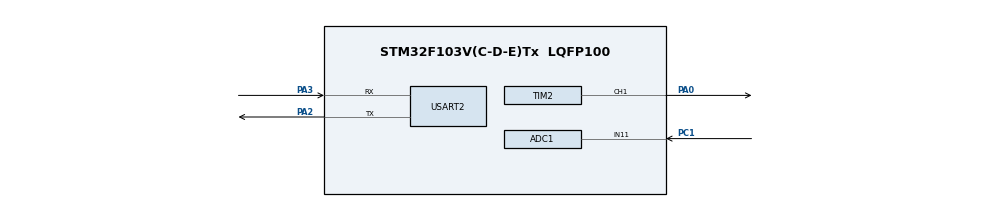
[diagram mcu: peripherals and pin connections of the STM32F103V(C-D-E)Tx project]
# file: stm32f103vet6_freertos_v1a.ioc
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ADC1.Channel-0\#ChannelRegularConversion=ADC_CHANNEL_11
ADC1.ContinuousConvMode=ENABLE
ADC1.NbrOfConversionFlag=1
ADC1.Rank-0\#ChannelRegularConversion=1
ADC1.SamplingTime-0\#ChannelRegularConversion=ADC_SAMPLETIME_1CYCLE_5
ADC1.master=1
FREERTOS.Tasks01=ControlTask,2,128,StartControlTask,Default,NULL,Dynamic,NULL,NULL;MonitorTask,0,128,StartMonitorTask,Default,NULL,Dynamic,NULL,NULL
FREERTOS.configUSE_NEWLIB_REENTRANT=1
Mcu.Family=STM32F1
Mcu.Name=STM32F103V(C-D-E)Tx
Mcu.Package=LQFP100
NVIC.PriorityGroup=NVIC_PRIORITYGROUP_4
NVIC.TIM3_IRQn=true\:15\:0\:false\:false\:true\:false\:false\:true\:true
NVIC.TimeBase=TIM3_IRQn
NVIC.TimeBaseIP=TIM3
OSC_IN.Mode=HSE-External-Oscillator
OSC_IN.Signal=RCC_OSC_IN
OSC_OUT.Mode=HSE-External-Oscillator
OSC_OUT.Signal=RCC_OSC_OUT
PA0-WKUP.Signal=S_TIM2_CH1_ETR
PA13.Mode=Serial_Wire
PA13.Signal=SYS_JTMS-SWDIO
PA14.Mode=Serial_Wire
PA14.Signal=SYS_JTCK-SWCLK
PA2.Mode=Asynchronous
PA2.Signal=USART2_TX
PA3.Mode=Asynchronous
PA3.Signal=USART2_RX
PC1.Signal=ADCx_IN11
ProjectManager.HeapSize=0x200
ProjectManager.StackSize=0x400
ProjectManager.TargetToolchain=STM32CubeIDE
RCC.APB1Freq_Value=8000000
RCC.APB2Freq_Value=8000000
SH.ADCx_IN11.0=ADC1_IN11,IN11
SH.S_TIM2_CH1_ETR.0=TIM2_CH1,PWM Generation1 CH1
TIM2.AutoReloadPreload=TIM_AUTORELOAD_PRELOAD_ENABLE
TIM2.Channel-PWM\ Generation1\ CH1=TIM_CHANNEL_1
TIM2.Period=99
TIM2.Prescaler=79
USART2.VirtualMode=VM_ASYNC
VP_FREERTOS_VS_CMSIS_V1.Mode=CMSIS_V1
VP_SYS_VS_tim3.Mode=TIM3
VP_TIM2_VS_ClockSourceINT.Mode=Internal
board=custom

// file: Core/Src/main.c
/* USER CODE BEGIN Header */
/**
  ******************************************************************************
  * @file           : main.c
  * @brief          : Main program body
  ******************************************************************************
  * @attention
  *
  * Copyright (c) 2026 STMicroelectronics.
  * All rights reserved.
  *
  * This software is licensed under terms that can be found in the LICENSE file
  * in the root directory of this software component.
  * If no LICENSE file comes with this software, it is provided AS-IS.
  *
  ******************************************************************************
  */
/* USER CODE END Header */
#include "main.h"
#include "cmsis_os.h"

ADC_HandleTypeDef hadc1;

TIM_HandleTypeDef htim2;

UART_HandleTypeDef huart2;

osThreadId ControlTaskHandle;
osThreadId MonitorTaskHandle;
/* USER CODE BEGIN PV */
volatile uint32_t adc_val = 0;
volatile uint32_t pwm_val = 0;
/* USER CODE END PV */

void SystemClock_Config(void);
static void MX_GPIO_Init(void);
static void MX_ADC1_Init(void);
static void MX_TIM2_Init(void);
static void MX_USART2_UART_Init(void);
void StartControlTask(void const * argument);
void StartMonitorTask(void const * argument);

int main(void)
{

  /* MCU Configuration--------------------------------------------------------*/

  /* Reset of all peripherals, Initializes the Flash interface and the Systick. */
  HAL_Init();

  /* Configure the system clock */
  SystemClock_Config();

  /* Initialize all configured peripherals */
  MX_GPIO_Init();
  MX_ADC1_Init();
  MX_TIM2_Init();
  MX_USART2_UART_Init();
  /* USER CODE BEGIN 2 */
  HAL_TIM_PWM_Start(&htim2, TIM_CHANNEL_1);
  HAL_ADC_Start(&hadc1);
  /* USER CODE END 2 */

  /* Create the thread(s) */
  /* definition and creation of ControlTask */
  osThreadDef(ControlTask, StartControlTask, osPriorityHigh, 0, 128);
  ControlTaskHandle = osThreadCreate(osThread(ControlTask), NULL);

  /* definition and creation of MonitorTask */
  osThreadDef(MonitorTask, StartMonitorTask, osPriorityNormal, 0, 128);
  MonitorTaskHandle = osThreadCreate(osThread(MonitorTask), NULL);

  /* Start scheduler */
  osKernelStart();

  /* We should never get here as control is now taken by the scheduler */

  /* Infinite loop */
  while (1)
  {

  }
}

void SystemClock_Config(void)
{
  RCC_OscInitTypeDef RCC_OscInitStruct = {0};
  RCC_ClkInitTypeDef RCC_ClkInitStruct = {0};
  RCC_PeriphCLKInitTypeDef PeriphClkInit = {0};

  /** Initializes the RCC Oscillators according to the specified parameters
  * in the RCC_OscInitTypeDef structure.
  */
  RCC_OscInitStruct.OscillatorType = RCC_OSCILLATORTYPE_HSI;
  RCC_OscInitStruct.HSIState = RCC_HSI_ON;
  RCC_OscInitStruct.HSICalibrationValue = RCC_HSICALIBRATION_DEFAULT;
  RCC_OscInitStruct.PLL.PLLState = RCC_PLL_NONE;
  if (HAL_RCC_OscConfig(&RCC_OscInitStruct) != HAL_OK)
  {
    Error_Handler();
  }

  /** Initializes the CPU, AHB and APB buses clocks
  */
  RCC_ClkInitStruct.ClockType = RCC_CLOCKTYPE_HCLK|RCC_CLOCKTYPE_SYSCLK
                              |RCC_CLOCKTYPE_PCLK1|RCC_CLOCKTYPE_PCLK2;
  RCC_ClkInitStruct.SYSCLKSource = RCC_SYSCLKSOURCE_HSI;
  RCC_ClkInitStruct.AHBCLKDivider = RCC_SYSCLK_DIV1;
  RCC_ClkInitStruct.APB1CLKDivider = RCC_HCLK_DIV1;
  RCC_ClkInitStruct.APB2CLKDivider = RCC_HCLK_DIV1;

  if (HAL_RCC_ClockConfig(&RCC_ClkInitStruct, FLASH_LATENCY_0) != HAL_OK)
  {
    Error_Handler();
  }
  PeriphClkInit.PeriphClockSelection = RCC_PERIPHCLK_ADC;
  PeriphClkInit.AdcClockSelection = RCC_ADCPCLK2_DIV2;
  if (HAL_RCCEx_PeriphCLKConfig(&PeriphClkInit) != HAL_OK)
  {
    Error_Handler();
  }
}

static void MX_ADC1_Init(void)
{

  ADC_ChannelConfTypeDef sConfig = {0};

  /** Common config
  */
  hadc1.Instance = ADC1;
  hadc1.Init.ScanConvMode = ADC_SCAN_DISABLE;
  hadc1.Init.ContinuousConvMode = ENABLE;
  hadc1.Init.DiscontinuousConvMode = DISABLE;
  hadc1.Init.ExternalTrigConv = ADC_SOFTWARE_START;
  hadc1.Init.DataAlign = ADC_DATAALIGN_RIGHT;
  hadc1.Init.NbrOfConversion = 1;
  if (HAL_ADC_Init(&hadc1) != HAL_OK)
  {
    Error_Handler();
  }

  /** Configure Regular Channel
  */
  sConfig.Channel = ADC_CHANNEL_11;
  sConfig.Rank = ADC_REGULAR_RANK_1;
  sConfig.SamplingTime = ADC_SAMPLETIME_1CYCLE_5;
  if (HAL_ADC_ConfigChannel(&hadc1, &sConfig) != HAL_OK)
  {
    Error_Handler();
  }

}

static void MX_TIM2_Init(void)
{

  TIM_ClockConfigTypeDef sClockSourceConfig = {0};
  TIM_MasterConfigTypeDef sMasterConfig = {0};
  TIM_OC_InitTypeDef sConfigOC = {0};

  htim2.Instance = TIM2;
  htim2.Init.Prescaler = 79;
  htim2.Init.CounterMode = TIM_COUNTERMODE_UP;
  htim2.Init.Period = 99;
  htim2.Init.ClockDivision = TIM_CLOCKDIVISION_DIV1;
  htim2.Init.AutoReloadPreload = TIM_AUTORELOAD_PRELOAD_ENABLE;
  if (HAL_TIM_Base_Init(&htim2) != HAL_OK)
  {
    Error_Handler();
  }
  sClockSourceConfig.ClockSource = TIM_CLOCKSOURCE_INTERNAL;
  if (HAL_TIM_ConfigClockSource(&htim2, &sClockSourceConfig) != HAL_OK)
  {
    Error_Handler();
  }
  if (HAL_TIM_PWM_Init(&htim2) != HAL_OK)
  {
    Error_Handler();
  }
  sMasterConfig.MasterOutputTrigger = TIM_TRGO_RESET;
  sMasterConfig.MasterSlaveMode = TIM_MASTERSLAVEMODE_DISABLE;
  if (HAL_TIMEx_MasterConfigSynchronization(&htim2, &sMasterConfig) != HAL_OK)
  {
    Error_Handler();
  }
  sConfigOC.OCMode = TIM_OCMODE_PWM1;
  sConfigOC.Pulse = 0;
  sConfigOC.OCPolarity = TIM_OCPOLARITY_HIGH;
  sConfigOC.OCFastMode = TIM_OCFAST_DISABLE;
  if (HAL_TIM_PWM_ConfigChannel(&htim2, &sConfigOC, TIM_CHANNEL_1) != HAL_OK)
  {
    Error_Handler();
  }
  HAL_TIM_MspPostInit(&htim2);

}

static void MX_USART2_UART_Init(void)
{

  huart2.Instance = USART2;
  huart2.Init.BaudRate = 115200;
  huart2.Init.WordLength = UART_WORDLENGTH_8B;
  huart2.Init.StopBits = UART_STOPBITS_1;
  huart2.Init.Parity = UART_PARITY_NONE;
  huart2.Init.Mode = UART_MODE_TX_RX;
  huart2.Init.HwFlowCtl = UART_HWCONTROL_NONE;
  huart2.Init.OverSampling = UART_OVERSAMPLING_16;
  if (HAL_UART_Init(&huart2) != HAL_OK)
  {
    Error_Handler();
  }

}

static void MX_GPIO_Init(void)
{

  /* GPIO Ports Clock Enable */
  __HAL_RCC_GPIOC_CLK_ENABLE();
  __HAL_RCC_GPIOA_CLK_ENABLE();

}

void StartControlTask(void const * argument)
{
  /* USER CODE BEGIN 5 */

  /* Infinite loop */
  for(;;)
  {
	  HAL_ADC_Start(&hadc1);
	          if (HAL_ADC_PollForConversion(&hadc1, 10) == HAL_OK)
	          {
	              adc_val = HAL_ADC_GetValue(&hadc1);
	              pwm_val = (adc_val * 99) / 4095;
	              __HAL_TIM_SET_COMPARE(&htim2, TIM_CHANNEL_1, pwm_val);
	          }

	          vTaskDelay(pdMS_TO_TICKS(10));

  }
  /* USER CODE END 5 */
}

void StartMonitorTask(void const * argument)
{
  /* USER CODE BEGIN StartMonitorTask */
	uint8_t tx_buffer[] = "Xin chao HV KTQS \r\n";
  /* Infinite loop */
  for(;;)
  {

	  HAL_UART_Transmit(&huart2, tx_buffer, sizeof(tx_buffer)-1, HAL_MAX_DELAY);

	  vTaskDelay(pdMS_TO_TICKS(1000));

  }

  /* USER CODE END StartMonitorTask */
}

void HAL_TIM_PeriodElapsedCallback(TIM_HandleTypeDef *htim)
{
  if (htim->Instance == TIM3)
  {
    HAL_IncTick();
  }
}

void Error_Handler(void)
{
  __disable_irq();
  while (1)
  {
  }
}
